# PAC55XX register map
Vendor: Qorvo, Inc.; Series: PAC55XX; File version: 1.0
ARM Cortex-M4 processor with FPU, running up to 150MHz with a set of analog and digital peripherals for power and motor control applications.
CPU: CM4 r0p1, little endian, MPU, FPU, vendor SysTick, 3 interrupt priority bits
Registers are 32-bit, read-write, reset 0x0 unless marked. A register's access mark holds for its fields unless they carry their own. Offsets are from the block's base; lines under a group give offsets from that group; [hi:lo] are bit positions; {n}, {i} and the like mark numbered series; 'fields as' and 'values as' point back to an identical list; <NAME> marks a mode.

## Memory map
0x40000000 ADC size 0x10000 — Analog to Digital Converter (ADC) and Dynamic Triggering and Sampling Engine (DTSE)
0x40010000 I2C size 0x10000 — Inter-Integrated Circuit
0x40020000 USARTA size 0x10000 — Universal Synchronous Asynchronous Receive Transmit A
0x40020000 SSPA size 0x10000 — Synchronous Serial Peripheral A
0x40030000 USARTB size 0x10000 — USART
0x40030000 SSPB size 0x10000 — Synchronous Serial Peripheral B
0x40040000 USARTC size 0x10000 — Universal Synchronous Asynchronous Receive Transmit C
0x40040000 SSPC size 0x10000 — Synchronous Serial Peripheral C
0x40050000 USARTD size 0x10000 — USART
0x40050000 SSPD size 0x10000 — Synchronous Serial Peripheral D
0x40060000 TIMERA size 0x10000
0x40070000 TIMERB size 0x10000
0x40080000 TIMERC size 0x10000
0x40090000 TIMERD size 0x10000
0x400A0000 CAN size 0x10000 — Controller Area Network
0x400B0000 GPTIMERA size 0x10000 — General Purpose Timer A
0x400C0000 GPTIMERB size 0x10000 — General Purpose Timer B
0x400D0000 MEMCTL size 0x400 — Memory Controller
0x400D0400 SCC size 0x400 — System and Clock Control
0x400D0800 WWDT size 0x400 — Windowed Watchdog Timer
0x400D0C00 RTC size 0x400 — Real-Time Clock (RTC) with Calendar
0x400D1000 CRC size 0x400 — Cyclic Redundancy Check
0x400D1400 GPIOA size 0x400 — General Purpose Input/Output A
0x400D1800 GPIOB size 0x400 — General Purpose Input/Output B
0x400D1C00 GPIOC size 0x400 — General Purpose Input/Output C
0x400D2000 GPIOD size 0x400 — General Purpose Input/Output D
0x400D2400 GPIOE size 0x400 — General Purpose Input/Output E
0x400D2800 GPIOF size 0x400 — General Purpose Input/Output F
0x400D2C00 GPIOG size 0x400 — General Purpose Input/Output G

## Interrupts
0 MEMCTL — MEMCTL Interrupt
1 WWDT — WWDT Interrupt
2 RTC — RTC Interrupt
3 ADC0 (ADC) — ADC 0 Interrupt
4 ADC1 (ADC) — ADC 1 Interrupt
5 ADC2 (ADC) — ADC 2 Interrupt
6 ADC3 (ADC) — ADC 3 Interrupt
7 TIMERA — Timer A Interrupt
8 TIMERB — Timer B Interrupt
9 TIMERC — Timer C Interrupt
10 TIMERD — Timer D Interrupt
11 TIMERAQEP (TIMERA) — Timer A QEP Interrupt
12 TIMERBQEP (TIMERB) — Timer B QEP Interrupt
13 TIMERCQEP (TIMERC) — Timer C QEP Interrupt
14 TIMERDQEP (TIMERD) — Timer D QEP Interrupt
15 GPIOA — GPIOA Interrupt
16 GPIOB — GPIO B Interrupt
17 GPIOC — GPIO C Interrupt
18 GPIOD — GPIO D Interrupt
19 GPIOE — GPIO E Interrupt
20 GPIOF — GPIO F Interrupt
21 GPIOG — GPIO G Interrupt
22 I2C — I2C Interrupt
23 USARTA_SSPA (USARTA) — USART/SSP A Interrupt
24 USARTB_SSPB (USARTB) — USART/SSP B Interrupt
25 USARTC_SSPC (USARTC) — USART/SSP C Interrupt
26 USARTD_SSPD (USARTD) — USART/SSP D Interrupt
27 CAN — CAN Interrupt
28 GPTIMERA — GPTimer A Interrupt
29 GPTIMERB — GPTimer B Interrupt
30 SCC — SCC Interrupt

## I2C — Inter-Integrated Circuit
Base 0x40010000
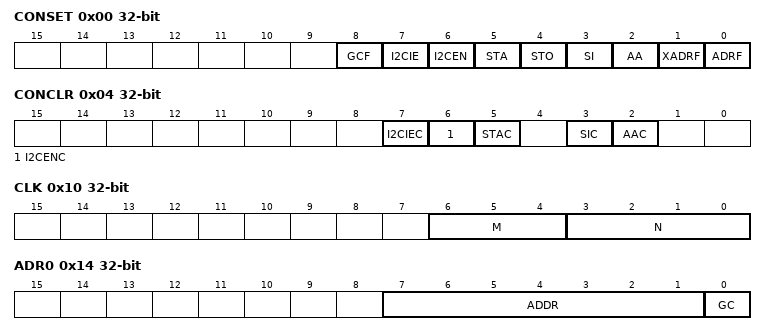
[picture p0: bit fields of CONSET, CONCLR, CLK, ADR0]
0x00 CONSET — I2C Control Set
  [8] GCF — General Call Flag
  [7] I2CIE — I2C Interrupt Enable
  [6] I2CEN — I2C Enable
  [5] STA wo — START Flag
  [4] STO wo — STOP Flag
  [3] SI ro — I2C Interrupt Flag
  [2] AA — Assert Acknowledge Flag
  [1] XADRF ro — Extended Slave Address Flag (10-bit addressing)
  [0] ADRF ro — Slave Address Flag
0x04 CONCLR — I2C Control Clear
  [7] I2CIEC — I2C Interrupt Disable
  [6] I2CENC — I2C Disable
  [5] STAC — START Flag Clear
  [3] SIC — I2C Interrupt Clear
  [2] AAC — Assert Acknowledge Clear
0x08 STAT — I2C Status
  [7:0] STATUS ro — Status code for I2C engine
    on read: 0=BUS_ERROR (Bus Error (master mode only)); 8=START (START condition transmitted); 16=RSTART (Repeated START condition transmitted); 24=SLAW_TX_ACK (Address and Write bit transmitted, ACK received); 32=SLAW_TX_NACK (Address and Write bit transmitted, NACK received); 40=MDATA_TX_ACK (Data byte transmitted in master mode, ACK received); 48=MDATA_TX_NACK (Data byte transmitted in master mode, NACK received); 56=ARB_LOST (Arbitration lost in address or data byte); 64=SLAR_TX_ACK (Address and read bit transmitted, ACK received); 72=SLAR_TX_NACK (Address and read bit transmitted, NACK received); 80=MDATA_RX_ACK (Data byte received in master mode, ACK transmitted); 88=MDATA_RX_NACK (Data byte received in master mode, NACK transmitted); 96=SLAW_RX_ACK (Slave address and write bit received, ACK transmitted); 104=ARB_LOST_SLAW_RX_ACK (Arbitration lost in address as master, slave address and write bit received, ACK transmitted); 112=GC_ACK (General call received, ACK returned); 128=SDATA_RX_ACK (Data byte received after slave address received, ACK transmitted); 136=SDATA_RX_NACK (Data byte received after slave address received, NACK transmitted); 144=DATA_RX_GC_ACK (Data byte received after general call address received, ACK transmitted); 160=STOP_RSTART_RX (STOP or repeated START condition received in slave mode); 168=SLAR_RX_ACK (Address and read bit received, ACK transmitted); 176=ARB_LOST_SLAR_RX_ACK (Arbitration lost in address as master, address and read bit received, ACK transmitted); 184=SDATA_TX_ACK (Data byte transmitted in slave mode, ACK received); 192=SDATA_TX_NACK (Data byte transmitted in slave mode, NACK received); 200=SDATA_LAST_TX_ACK (Last data byte transmitted in slave mode, ACK received); 208=SDATA_LAST_TX_NACK (Last data byte transmitted in slave mode, NACK received); 224=SECOND_ADDR_TX_ACK (Second address byte received in slave mode, ACK transmitted); 240=SECOND_ADDR_TX_NACK (Second address byte received in slave mode, NACK transmitted); 248=NO_INFO (No relevant status information)
0x0C DAT — I2C Data
  [7:0] DATA — Data values received or to be transmitted
0x10 CLK — I2C Clock Control
  [6:4] M — Fsamp = PCLK / 2^M
  [3:0] N — Fscl = PCLK / (2^M * (N+1) * 10)
0x14 ADR0 — I2C Slave Address 0
  [7:1] ADDR — Slave Address
  [0] GC — General Call Enable
0x18 ADRM0 — I2C Slave Address Mask 0
  [7:1] MASK — Slave Address Mask
0x1C XADR0 — I2C Extended Slave Address 0
  [10:1] ADDR — Extended Slave Address
0x20 XADRM0 — I2C Extended Slave Address Mask 0
  [10:1] MASK — Extended Slave Address Mask
0x24 RST — I2C Software Reset
  [7:0] RST
    7=RESET (Perform I2C software reset)
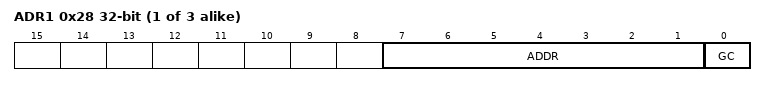
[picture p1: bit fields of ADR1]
{0x20+8i} ADR{i} (i=1..3) — I2C Slave Address {i}
  [7:1] ADDR — Slave Address
  [0] GC — General Call Enable
{0x24+8i} ADRM{i} (i=1..3) — I2C Slave Address Mask {i}
  [7:1] MASK — Slave Address Mask

## Licence text in the file
Apache-2.0 OR MIT
